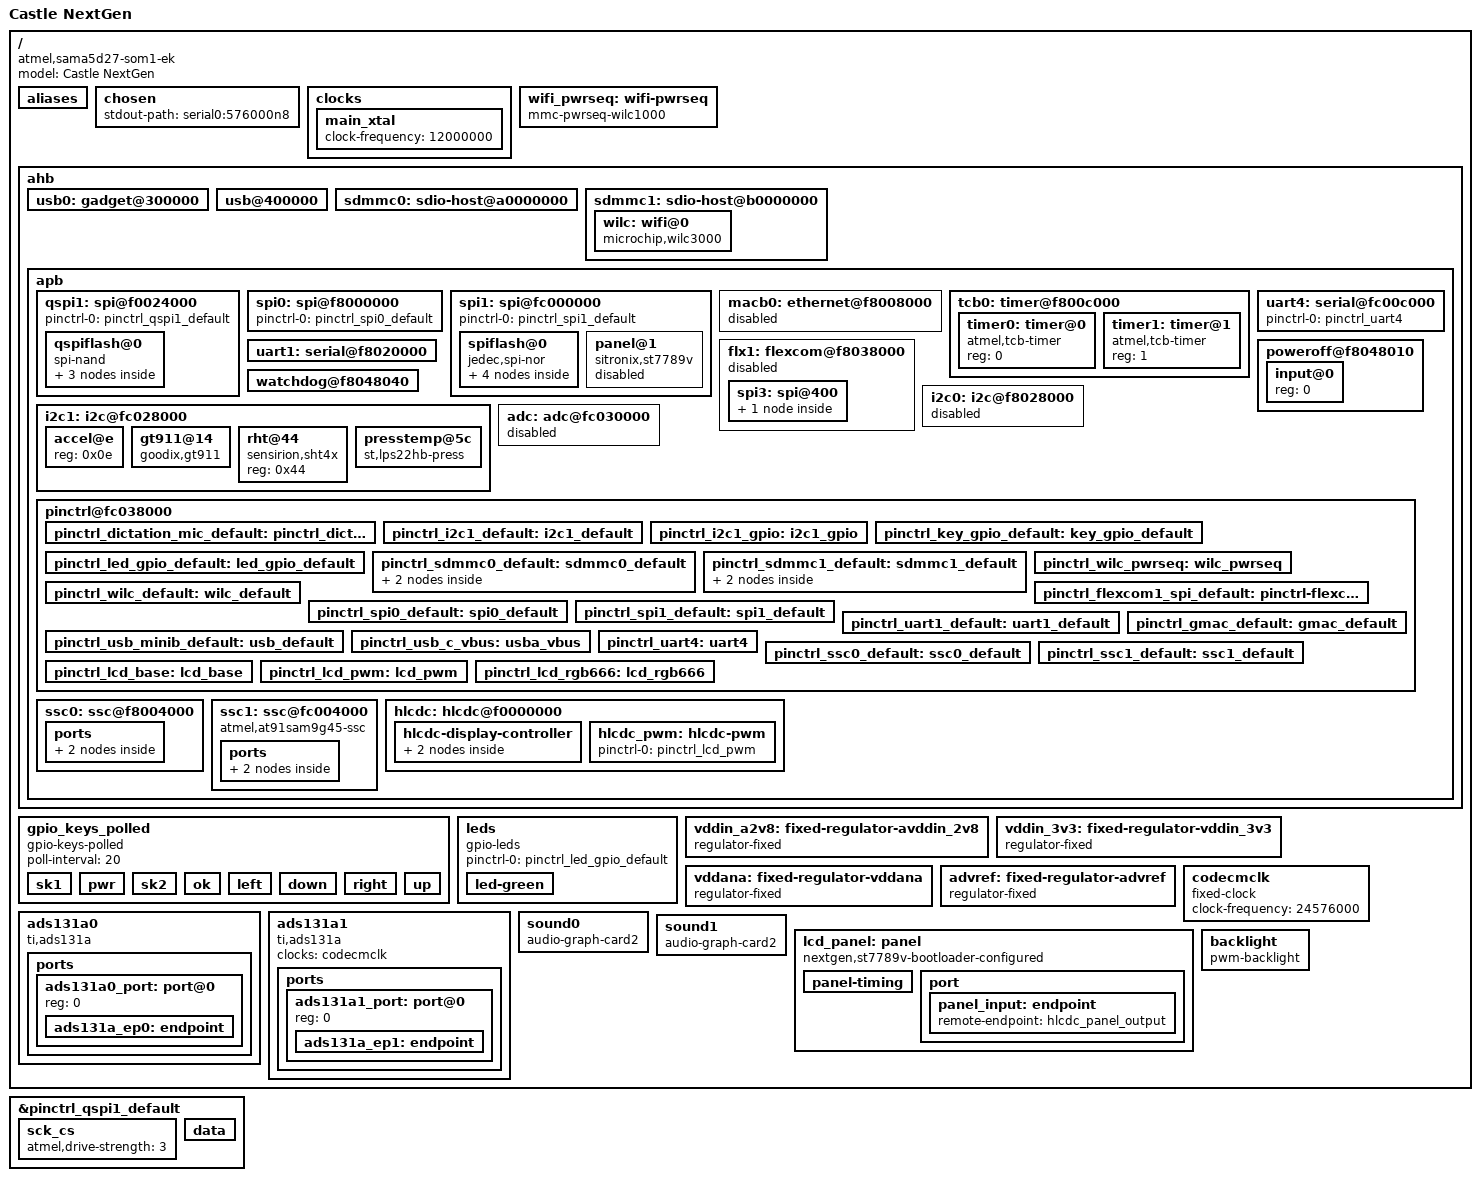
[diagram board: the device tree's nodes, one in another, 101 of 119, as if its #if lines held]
//#define NEXTGEN_WIFI_SDIO 1
#define NEXTGEN_LCD_RGB 1

// SPDX-License-Identifier: (GPL-2.0+ OR MIT)
/*
* at91-sama5d27_som1_ek.dts - Device Tree file for SAMA5D27-SOM1-EK board
*
*  Copyright (c) 2017, Microchip Technology Inc.
*                2016 Nicolas Ferre <nicolas.ferre@atmel.com>
*                2017 Cristian Birsan <cristian.birsan@microchip.com>
*                2017 Claudiu Beznea <claudiu.beznea@microchip.com>
*/
/dts-v1/;
#include "at91-sama5d27_som1.dtsi"
#include <dt-bindings/mfd/atmel-flexcom.h>
#include <dt-bindings/gpio/gpio.h>
#include <dt-bindings/interrupt-controller/irq.h>
#include <dt-bindings/input/input.h>

/ {
	model = "Castle NextGen";
	compatible = "atmel,sama5d27-som1-ek", "atmel,sama5d27-som1", "atmel,sama5d27", "atmel,sama5d2", "atmel,sama5";
	
	aliases {
		serial0 = &uart1;	/* DBGU */
		serial1 = &uart4;	/* mikro BUS 1 */
		i2c1 = &i2c1;
		ssc0 = &ssc0;
		ssc1 = &ssc1;
	};
	
	chosen {
		stdout-path = "serial0:576000n8";
	};

	/* NextGen hardware uses a 12 MHz main crystal; the upstream SoM uses 24 MHz. */
	clocks {
		main_xtal {
			clock-frequency = <12000000>;
		};
	};
	
	wifi_pwrseq: wifi-pwrseq {
		compatible = "mmc-pwrseq-wilc1000";
		reset-gpios = <&pioA PIN_PA27 GPIO_ACTIVE_HIGH>;
		powerdown-gpios = <&pioA PIN_PD26 GPIO_ACTIVE_HIGH>;
		pinctrl-names = "default";
		pinctrl-0 = <&pinctrl_wilc_pwrseq>;
#if NEXTGEN_WIFI_SDIO
		status = "okay";
#else
		status = "disabled";
#endif	
	};
	
	ahb {
		usb0: gadget@300000 {
			atmel,vbus-gpio = <&pioA PIN_PA31 GPIO_ACTIVE_HIGH>;
			pinctrl-names = "default";
			pinctrl-0 = <&pinctrl_usb_c_vbus>;
			status = "okay";
		};
		
		usb@400000 {
			num-ports = <3>;
			atmel,vbus-gpio = <0 &pioA PIN_PC0 GPIO_ACTIVE_HIGH 0>;
			pinctrl-names = "default";
			pinctrl-0 = <&pinctrl_usb_minib_default>;
			status = "okay";
		};
		
		sdmmc0: sdio-host@a0000000 {
			bus-width = <4>;
			pinctrl-names = "default";
			pinctrl-0 = <&pinctrl_sdmmc0_default>;
			status = "okay";
			non-removable;
			no-1-8-v;
			disable-wp;
		};
		
		sdmmc1: sdio-host@b0000000 {
			#address-cells = <1>;
			#size-cells = <0>;
			
			bus-width = <4>;
			max-frequency = <4000000>;
			no-1-8-v;
			non-removable;
			disable-wp;
			mmc-pwrseq = <&wifi_pwrseq>;
			
			pinctrl-names = "default";
			pinctrl-0 = <&pinctrl_sdmmc1_default>;
#if NEXTGEN_WIFI_SDIO
			status = "okay";
#else
			status = "disabled";
#endif
			wilc: wifi@0 {
				compatible = "microchip,wilc3000", "microchip,wilc1000";
				reg = <0>;
				
				interrupt-parent = <&pioA>;
				interrupts = <PIN_PB2 IRQ_TYPE_NONE>;
				
				pinctrl-names = "default";
				pinctrl-0 = <&pinctrl_wilc_default>;
				status = "okay";
			};
		};
		
		apb {
			
			qspi1: spi@f0024000 {
				pinctrl-names = "default";
				pinctrl-0 = <&pinctrl_qspi1_default>;
				status = "okay";

				/* Remove the SoM SPI-NOR; NextGen has SPI-NAND on QSPI1 CS0. */
				/delete-node/ flash@0;

				qspiflash@0 {
					compatible = "spi-nand";
					reg = <0>;
					spi-max-frequency = <90000000>;
					spi-rx-bus-width = <4>;
					spi-tx-bus-width = <1>;
					partitions {
						compatible = "fixed-partitions";
						#address-cells = <1>;
						#size-cells = <1>;
						
						boot@0 {
							/*
							 * Production boot objects are static volumes in this
							 * small UBI device. Keeping it separate from rootfs
							 * bounds the bootloader's UBI attach scan.
							 */
							label = "boot";
							reg = <0x00000000 0x00880000>;   /* 8.5 MiB */
						};
						
						rootfs@880000 {
							label = "rootfs";
							reg = <0x00880000 0x08000000>; /* 128 MiB; remainder intentionally spare */
						};
					};
				};
			};
			
			spi0: spi@f8000000 {
				pinctrl-names = "default";
				pinctrl-0 = <&pinctrl_spi0_default>;
				status = "okay";
			};
			
			spi1: spi@fc000000 {
				pinctrl-names = "default";
				pinctrl-0 = <&pinctrl_spi1_default>;
				status = "okay";
				
				spiflash@0 {
					compatible = "jedec,spi-nor";
					reg = <0>;
					spi-max-frequency = <50000000>;
					partitions {
						compatible = "fixed-partitions";
						#address-cells = <1>;
						#size-cells = <1>;
						
						partition@0 {
							label = "at91bootstrap";
							reg = <0x0 0x8000>;
						};
						partition@8000 {
							label = "uboot";
							reg = <0x8000 0x138000>;
						};
						partition@140000 {
							/*
							 * MX25V1635F is 2 MiB total. The 128 KiB environment
							 * partition contains two independent 64 KiB erase slots:
							 *   +0x00000 primary,   16 KiB payload
							 *   +0x10000 redundant, 16 KiB payload
							 * Linux userspace must keep using the partition label
							 * rather than relying on a fixed /dev/mtd number.
							 */
							label = "uboot-env";
							reg = <0x140000 0x020000>;
						};
					};
				};
				
				panel@1{
					compatible = "sitronix,st7789v";
					reg = <1>;
					pinctrl-names = "default";
					spi-max-frequency = <32000000>;
					txbuflen = <16384>;
					fps = <30>;
					buswidth = <8>;
					rotate = <0>;
					width = <240>;
					height = <320>;
					reset-gpios = <&pioA PIN_PC9 GPIO_ACTIVE_LOW>;
					dc-gpios = <&pioA PIN_PC7 0>;
					debug = <0>;
#if NEXTGEN_LCD_RGB
					status = "disabled";
#else
					status = "okay";
#endif
					/*port {
						panel_input: endpoint {
							remote-endpoint = <&hlcdc_panel_output>;
						};
					};*/
				};
				/*
				panel@1 {
					compatible = "sitronix,st7789v";
					reg = <1>;
					reset-gpios = <&pioA PIN_PC9 GPIO_ACTIVE_LOW>;
					dc-gpios = <&pioA PIN_PC7 0>;
					buswidth = <8>;
					backlight = <&hlcdc_pwm>;
					spi-max-frequency = <100000>;
					spi-cpol;
					spi-cpha;
					debug = <9>;
					width = <240>;
					height = <320>;
					rotate = <90>;
					x-offset = <0>;
					y-offset = <0>;
					vcom = <0x19>;
					gctrl = <0x35>;
					vrhs = <0x12>;
					vdvs = <0x20>;
					mdac = <0x00>;
					gamma = <0x01>;
					colmod = <0x05>;
					lcm = <0x2c>;
					porch-param = [0c 0c 00 33 33];
					cmd2en-param = [5a 69 02 01];
					pwctrl1-param = [a4 a1];
					pvgam-param = [D0 04 0D 11 13 2B 3F 54 4C 18 0D 0B 1F 23];
					nvgam-param = [D0 04 0C 11 13 2C 3F 44 51 2F 1F 1F 20 23];
					ram-param = [00 F0];
					rgb-param = [CD 08 14];
				};
				*/
			};
			
			macb0: ethernet@f8008000 {
				/* Ethernet is not fitted/used on NextGen. */
				status = "disabled";
			};
			
			tcb0: timer@f800c000 {
				timer0: timer@0 {
					compatible = "atmel,tcb-timer";
					reg = <0>;
				};
				
				timer1: timer@1 {
					compatible = "atmel,tcb-timer";
					reg = <1>;
				};
			};
			
			uart1: serial@f8020000 {
				pinctrl-names = "default";
				pinctrl-0 = <&pinctrl_uart1_default>;
				atmel,use-dma-rx;
				atmel,use-dma-tx;
				status = "okay";
			};
			
			
			flx1: flexcom@f8038000 {
				atmel,flexcom-mode = <ATMEL_FLEXCOM_MODE_SPI>;
				pinctrl-names = "default";
				pinctrl-0 = <&pinctrl_flexcom1_spi_default>;
#if NEXTGEN_WIFI_SDIO
				status = "disabled";
#else
				status = "okay";
#endif			
				spi3: spi@400 {
					status = "okay";
					
					wilc_spi@0 {
						compatible = "microchip,wilc3000", "microchip,wilc1000";
						spi-max-frequency = <20000000>;
						interrupt-parent = <&pioA>;
						interrupts = <PIN_PB2 0>;
						reset-gpios = <&pioA PIN_PA27 GPIO_ACTIVE_LOW>;
						enable-gpios = <&pioA PIN_PD26 GPIO_ACTIVE_HIGH>;
						reg = <0>;
						status = "okay";
					};
				};
			};
			/**/
			uart4: serial@fc00c000 {
				//atmel,use-dma-rx;
				//atmel,use-dma-tx;
				pinctrl-names = "default";
				pinctrl-0 = <&pinctrl_uart4>;
				status = "okay";
			};
			
			poweroff@f8048010 {
				debounce-delay-us = <976>;
				atmel,wakeup-rtc-timer;
				
				input@0 {
					reg = <0>;
				};
			};
			
			watchdog@f8048040 {
				status = "okay";
			};
			
			
			
			i2c0: i2c@f8028000 {
				status = "disabled";
			};
			i2c1: i2c@fc028000 {
				/delete-property/ dmas;
				/*
				i2c-analog-filter;
				i2c-digital-filter;
				i2c-digital-filter-width-ns = <35>;*/
				pinctrl-names = "default", "gpio";
				pinctrl-0 = <&pinctrl_i2c1_default>;
				pinctrl-1 = <&pinctrl_i2c1_gpio>;
				sda-gpios = <&pioA PIN_PD19 GPIO_ACTIVE_HIGH>;
				scl-gpios = <&pioA PIN_PD20 (GPIO_ACTIVE_HIGH | GPIO_OPEN_DRAIN)>;
				status = "okay";
				
				/*
				*/
				accel@e {
					compatible = "";
					reg = <0x0e>;
				};
				
				gt911@14 {
					compatible = "goodix,gt911";
					reg = <0x14>;
					interrupt-parent = <&pioA>;
					interrupts = <PIN_PD7 IRQ_TYPE_EDGE_FALLING>;
					touchscreen-size-x = <240>;
					touchscreen-size-y = <320>;

					/*
					 * The Goodix driver explicitly drives INT and RESET during
					 * its address-selection/reset sequence, so these GPIO
					 * descriptors must be non-inverting even though the runtime
					 * interrupt itself is active low.
					 */
					irq-gpios = <&pioA PIN_PD7 GPIO_ACTIVE_HIGH>;
					reset-gpios = <&pioA PIN_PD5 GPIO_ACTIVE_HIGH>;
					AVDD28-supply = <&vddin_a2v8>;
					VDDIO-supply = <&vddin_3v3>;
				};
				rht@44 {
					compatible = "sensirion,sht4x";
					reg = <0x44>;
				};
				presstemp@5c {
					compatible = "st,lps22hb-press";
					reg = <0x5c>;
					//st,drdy-int-pin = <0>; 
					vdd-supply = <&vddin_3v3>;
					vddio-supply = <&vddin_3v3>;
				};
				
				
			};
			
			adc: adc@fc030000 {
				vddana-supply = <&vddana>;
				vref-supply = <&advref>;
				pinctrl-names = "default";
				pinctrl-0 = <&pinctrl_dictation_mic_default>;
				
				status = "disabled";
			};
			
			pinctrl@fc038000 {
				
				pinctrl_dictation_mic_default: pinctrl_dictation_mic {
					pinmux =
					<PIN_PD25__GPIO>;
					bias-disable;
				};
				
				pinctrl_i2c1_default: i2c1_default {
					pinmux = <PIN_PD19__TWD1>,
					<PIN_PD20__TWCK1>;
					bias-disable;
				};
				
				pinctrl_i2c1_gpio: i2c1_gpio {
					pinmux = <PIN_PD19__GPIO>,
					<PIN_PD20__GPIO>;
					bias-disable;
				};
				
				
				pinctrl_key_gpio_default: key_gpio_default {
					pinmux = <PIN_PA29__GPIO>;
					bias-pull-up;
				};
				
				pinctrl_led_gpio_default: led_gpio_default {
					pinmux = <PIN_PB12__GPIO>;
					bias-pull-up;
				};
				
				pinctrl_sdmmc0_default: sdmmc0_default {
					cmd_data {
						pinmux = <PIN_PA1__SDMMC0_CMD>,
						<PIN_PA2__SDMMC0_DAT0>,
						<PIN_PA3__SDMMC0_DAT1>,
						<PIN_PA4__SDMMC0_DAT2>,
						<PIN_PA5__SDMMC0_DAT3>;
						bias-disable;
					};
					
					ck_cd_vddsel {
						pinmux = <PIN_PA0__SDMMC0_CK>,
						<PIN_PA11__SDMMC0_VDDSEL>,
						<PIN_PA13__SDMMC0_CD>;
						bias-disable;
					};
				};
				pinctrl_sdmmc1_default: sdmmc1_default {
					cmd_data {
						pinmux =
						<PIN_PA28__SDMMC1_CMD>,
						<PIN_PA18__SDMMC1_DAT0>,
						<PIN_PA19__SDMMC1_DAT1>,
						<PIN_PA20__SDMMC1_DAT2>,
						<PIN_PA21__SDMMC1_DAT3>;
						atmel,drive-strength = <3>;
						bias-disable;
					};
					
					ck_cd_vddsel {
						pinmux =
						<PIN_PA22__SDMMC1_CK>;
						/*,
						<PIN_PA30__SDMMC1_CD>;*/
						atmel,drive-strength = <3>;
						bias-disable;
					};
				};
				pinctrl_wilc_pwrseq: wilc_pwrseq {
					pinmux = <PIN_PA27__GPIO>,
					<PIN_PD26__GPIO>;
					bias-disable;
				};
				
				pinctrl_wilc_default: wilc_default {
					pinmux = <PIN_PB2__GPIO>;
					bias-disable;
				};
				
				pinctrl_flexcom1_spi_default: pinctrl-flexcom1_spi {
					pinmux =
					<PIN_PA22__FLEXCOM1_IO2>,
					<PIN_PA23__FLEXCOM1_IO1>,
					<PIN_PA24__FLEXCOM1_IO0>,
					<PIN_PA25__FLEXCOM1_IO3>,
					<PIN_PA26__FLEXCOM1_IO4>;
					bias-disable;
					atmel,drive-strength = <3>;
				};
				
				
				pinctrl_spi0_default: spi0_default {
					pinmux = <PIN_PA14__SPI0_SPCK>,
					<PIN_PA15__SPI0_MOSI>,
					<PIN_PA16__SPI0_MISO>,
					<PIN_PA17__SPI0_NPCS0>;
					bias-disable;
				};
				
				pinctrl_spi1_default: spi1_default {
					pinmux = <PIN_PC1__SPI1_SPCK>,
					<PIN_PC2__SPI1_MOSI>,
					<PIN_PC3__SPI1_MISO>,
					<PIN_PC4__SPI1_NPCS0>,
					<PIN_PC5__SPI1_NPCS1>,
					<PIN_PC6__SPI1_NPCS2>;
					bias-disable;
					atmel,drive-strength = <3>;
				};
				
				pinctrl_uart1_default: uart1_default {
					pinmux = <PIN_PD2__URXD1>,
					<PIN_PD3__UTXD1>;
					bias-disable;
				};
				
				pinctrl_gmac_default: gmac_default {
					pinmux =
					<PIN_PD9__GTXCK>,
					<PIN_PD10__GTXEN>,
					<PIN_PD11__GRXDV>,
					<PIN_PD12__GRXER>,
					<PIN_PD13__GRX0>,
					<PIN_PD14__GRX1>,
					<PIN_PD15__GTX0>,
					<PIN_PD16__GTX1>,
					<PIN_PD17__GMDC>,
					<PIN_PD18__GMDIO>;
					bias-disable;
				};
				
				pinctrl_usb_minib_default: usb_default {
					pinmux = <PIN_PC0__GPIO>;
					bias-disable;
				};
				
				pinctrl_usb_c_vbus: usba_vbus {
					pinmux = <PIN_PA31__GPIO>;
					bias-disable;
				};
				
				pinctrl_uart4: uart4 {
					pinmux = <PIN_PB3__URXD4>,
					<PIN_PB4__UTXD4>;
					bias-disable;
				};
				
				pinctrl_ssc0_default: ssc0_default {
					pinmux =
					<PIN_PB20__TK0>,
					<PIN_PB21__TF0>,
					<PIN_PB22__TD0>,
					<PIN_PB23__RD0>,
					<PIN_PB24__RK0>,
					<PIN_PB25__RF0>;
					bias-disable;
				};
				
				pinctrl_ssc1_default: ssc1_default {
					pinmux =
					<PIN_PB14__TK1>,
					<PIN_PB15__TF1>,
					<PIN_PB16__TD1>,
					<PIN_PB17__RD1>,
					<PIN_PB18__RK1>,
					<PIN_PB19__RF1>;
					bias-disable;
				};
				
				pinctrl_lcd_base: lcd_base {
					pinmux =
					<PIN_PD0__LCDPCK>,
					<PIN_PD1__LCDDEN>,
					<PIN_PC29__LCDDISP>,
					<PIN_PC30__LCDVSYNC>,
					<PIN_PC31__LCDHSYNC>;
					bias-disable;
				};
				
				pinctrl_lcd_pwm: lcd_pwm {
					pinmux = <PIN_PC28__LCDPWM>;
					bias-disable;
				};
				
				pinctrl_lcd_rgb666: lcd_rgb666{
					pinmux =
					<PIN_PC10__LCDDAT2>,
					<PIN_PC11__LCDDAT3>,
					<PIN_PC12__LCDDAT4>,
					<PIN_PC13__LCDDAT5>,
					<PIN_PC14__LCDDAT6>,
					<PIN_PC15__LCDDAT7>,
					<PIN_PC16__LCDDAT10>,
					<PIN_PC17__LCDDAT11>,
					<PIN_PC18__LCDDAT12>,
					<PIN_PC19__LCDDAT13>,
					<PIN_PC20__LCDDAT14>,
					<PIN_PC21__LCDDAT15>,
					<PIN_PC22__LCDDAT18>,
					<PIN_PC23__LCDDAT19>,
					<PIN_PC24__LCDDAT20>,
					<PIN_PC25__LCDDAT21>,
					<PIN_PC26__LCDDAT22>,
					<PIN_PC27__LCDDAT23>;
					bias-disable;
				};
			};
			
			ssc0: ssc@f8004000 {
				status = "okay";
				pinctrl-names = "default";
				pinctrl-0 = <&pinctrl_ssc0_default>;
				#sound-dai-cells = <0>;
				atmel,clk-from-rk-pin;
				dmas = <&dma1
				(AT91_XDMAC_DT_MEM_IF(0) | AT91_XDMAC_DT_PER_IF(1) |
				AT91_XDMAC_DT_PERID(21))>,
				<&dma1
				(AT91_XDMAC_DT_MEM_IF(0) | AT91_XDMAC_DT_PER_IF(1) |
				AT91_XDMAC_DT_PERID(22))>;
				ports {
					#address-cells = <1>;
					#size-cells = <0>;
					
					ssc0_port: port@0 {
						reg = <0>;
						
						ssc0_ep: endpoint {
							remote-endpoint = <&ads131a_ep0>;
							dai-format = "dsp_a";
							dai-tdm-slot-num = <3>;
							dai-tdm-slot-width = <24>;
							
						};
					};
				};
			};
			
			
			ssc1: ssc@fc004000 {
				compatible = "atmel,at91sam9g45-ssc";
				reg = <0xfc004000 0x4000>;
				interrupts = <44 IRQ_TYPE_LEVEL_HIGH 4>;
				clocks = <&pmc PMC_TYPE_PERIPHERAL 44>;
				clock-names = "pclk";
				status = "okay";
				pinctrl-names = "default";
				pinctrl-0 = <&pinctrl_ssc1_default>;
				#sound-dai-cells = <0>;
				atmel,clk-from-rk-pin;
				dmas = <&dma1
				(AT91_XDMAC_DT_MEM_IF(0) | AT91_XDMAC_DT_PER_IF(1) |
				AT91_XDMAC_DT_PERID(23))>,
				<&dma1
				(AT91_XDMAC_DT_MEM_IF(0) | AT91_XDMAC_DT_PER_IF(1) |
				AT91_XDMAC_DT_PERID(24))>;
				dma-names = "tx", "rx";
				ports {
					#address-cells = <1>;
					#size-cells = <0>;
					
					ssc1_port: port@0 {
						reg = <0>;
						
						ssc1_ep: endpoint {
							remote-endpoint = <&ads131a_ep1>;
							dai-format = "dsp_a";
							dai-tdm-slot-num = <5>;
							dai-tdm-slot-width = <24>;
							
						};
					};
				};
			};
			
			hlcdc: hlcdc@f0000000 {
				status = "okay";
				hlcdc-display-controller {
					pinctrl-names = "default";
					pinctrl-0 = <&pinctrl_lcd_base &pinctrl_lcd_rgb666>;
					port@0 {
						hlcdc_panel_output: endpoint@0 {
							bus-width = <18>;
#if NEXTGEN_LCD_RGB
							remote-endpoint = <&panel_input>;
#endif
						};
					};
				};
				hlcdc_pwm: hlcdc-pwm {
					pinctrl-names = "default";
					pinctrl-0 = <&pinctrl_lcd_pwm>;
				};
				
			};
			/*
			sha: crypto@f0028000 {
				status = "disabled";
			};
			
			aes: crypto@f002c000 {
				status = "disabled";
			};
			tdes: crypto@fc044000 {
				status = "disabled";
			};
			*/
		};
	};
	
	gpio_keys_polled {
		compatible = "gpio-keys-polled";
		poll-interval = <20>;
		
		pinctrl-names = "default";
		
		sk1 {
			label = "GPIO Key Sk1";
			linux,code = <102>;
			gpios = <&pioBU 0 0x11>;
		};
		
		pwr {
			label = "GPIO Key Power";
			linux,code = <14>;
			gpios = <&pioBU 1 0x11>;
		};
		
		sk2 {
			label = "GPIO Key SK2";
			linux,code = <107>;
			gpios = <&pioBU 2 0x11>;
		};
		
		ok {
			label = "GPIO Key Ok";
			linux,code = <28>;
			gpios = <&pioBU 3 0x11>;
		};
		
		left {
			label = "GPIO Key Left";
			linux,code = <105>;
			gpios = <&pioBU 4 0x11>;
			autorepeat;
		};
		
		down {
			label = "GPIO Key Down";
			linux,code = <108>;
			gpios = <&pioBU 5 0x11>;
			autorepeat;
		};
		
		right {
			label = "GPIO Key Right";
			linux,code = <106>;
			gpios = <&pioBU 6 0x11>;
			autorepeat;
		};
		
		up {
			label = "GPIO Key Up";
			linux,code = <103>;
			gpios = <&pioBU 7 0x11>;
			autorepeat;
		};
		
	};
	
	leds {
		compatible = "gpio-leds";
		pinctrl-names = "default";
		pinctrl-0 = <&pinctrl_led_gpio_default>;
		status = "okay"; /* Conflict with pwm0. */
		
		led-green {
			label = "green";
			gpios = <&pioA PIN_PB12 GPIO_ACTIVE_HIGH>;
			linux,default-trigger = "heartbeat";
		};
		
	};
	
	vddin_a2v8: fixed-regulator-avddin_2v8 {
		compatible = "regulator-fixed";
		
		regulator-name = "AVDD2V8";
		regulator-min-microvolt = <2800000>;
		regulator-max-microvolt = <2800000>;
		regulator-always-on;
		regulator-boot-on;
		status = "okay";
	};
	vddin_3v3: fixed-regulator-vddin_3v3 {
		compatible = "regulator-fixed";
		
		regulator-name = "VDDIN_3V3";
		regulator-min-microvolt = <3300000>;
		regulator-max-microvolt = <3300000>;
		regulator-always-on;
		regulator-boot-on;
		status = "okay";
	};
	
	vddana: fixed-regulator-vddana {
		compatible = "regulator-fixed";
		
		regulator-name = "VDDANA";
		regulator-min-microvolt = <3300000>;
		regulator-max-microvolt = <3300000>;
		regulator-always-on;
		regulator-boot-on;
		vin-supply = <&vddin_3v3>;
		status = "okay";
	};
	
	advref: fixed-regulator-advref {
		compatible = "regulator-fixed";
		
		regulator-name = "advref";
		regulator-min-microvolt = <3300000>;
		regulator-max-microvolt = <3300000>;
		regulator-always-on;
		regulator-boot-on;
		vin-supply = <&vddana>;
		status = "okay";
	};
	
	codecmclk: codecmclk {
		compatible = "fixed-clock";
		#clock-cells = <0>;
		clock-frequency = <24576000>;
	};
	
	ads131a0: ads131a0 {
		compatible = "ti,ads131a";
		status = "okay";
		
		#sound-dai-cells = <0>;
		
		clocks = <&codecmclk>;
		clock-names = "mclk";
		codecreset-gpios = <&pioA PIN_PB1 GPIO_ACTIVE_LOW>;
		
		ports {
			#address-cells = <1>;
			#size-cells = <0>;
			
			ads131a0_port: port@0 {
				reg = <0>;
				
				ads131a_ep0: endpoint {
					remote-endpoint = <&ssc0_ep>;
					dai-format = "dsp_a";
				};
			};
		};
	};
	
	
	ads131a1: ads131a1 {
		compatible = "ti,ads131a";
		status = "okay";
		
		#sound-dai-cells = <0>;
		
		clocks = <&codecmclk>;
		clock-names = "mclk";
		
		ports {
			#address-cells = <1>;
			#size-cells = <0>;
			
			ads131a1_port: port@0 {
				reg = <0>;
				
				ads131a_ep1: endpoint {
					remote-endpoint = <&ssc1_ep>;
					dai-format = "dsp_a";
				};
			};
		};
	};
	
	sound0 {
		compatible = "audio-graph-card2";
		label = "ads131a0-ssc0";
		
		links = <&ssc0_port>;
	};
	sound1 {
		compatible = "audio-graph-card2";
		label = "ads131a1-ssc1";
		
		links = <&ssc1_port>;
	};
	
#if NEXTGEN_LCD_RGB
	/*
	 * ST7789V is initialised into RGB666 mode by U-Boot. Linux does not
	 * access its SPI control interface; panel-dpi supplies only the fixed
	 * timing and DRM graph endpoint for the HLCDC RGB output.
	 */
	lcd_panel: panel {
		compatible = "nextgen,st7789v-bootloader-configured", "panel-dpi";
		power-supply = <&vddin_3v3>;
		backlight = <&backlight>;
		status = "okay";

		panel-timing {
			clock-frequency = <6400000>;

			hactive = <240>;
			vactive = <320>;

			hfront-porch = <6>;
			hsync-len = <10>;
			hback-porch = <10>;

			vfront-porch = <5>;
			vsync-len = <3>;
			vback-porch = <1>;

			hsync-active = <0>;
			vsync-active = <0>;
			de-active = <1>;
			pixelclk-active = <0>;
		};

		port {
			panel_input: endpoint {
				remote-endpoint = <&hlcdc_panel_output>;
			};
		};
	};
#endif

	backlight: backlight {
		compatible = "pwm-backlight";
		
		pwms = <&hlcdc_pwm 0 50000 0>;
		
		brightness-levels = <0 255>;
		num-interpolated-steps = <255>;
		default-brightness-level = <128>;
		
		power-supply = <&vddin_3v3>;
		status = "okay";
	};
};


/*
 * The 6.18 SoM DTSI owns the QSPI1 pinmux.  Preserve the NextGen
 * electrical settings without duplicating that pinctrl definition.
 */
&pinctrl_qspi1_default {
	sck_cs {
		atmel,drive-strength = <3>;
	};

	data {
		/delete-property/ bias-pull-up;
		bias-disable;
		atmel,drive-strength = <3>;
	};
};
